# WB32F10x register map
File version: 1.2
CPU: CM3 r2p0, little endian, MPU, no FPU, 4 interrupt priority bits
Registers are 32-bit, read-write, reset 0x0 unless marked. A register's access mark holds for its fields unless they carry their own. Offsets are from the block's base; [hi:lo] are bit positions; lines under a group give offsets from that group; {n}, {i} and the like mark numbered series; 'fields as' and 'values as' point back to an identical list.

## ADC — Analog to digital conversion
Base 0x40003C00
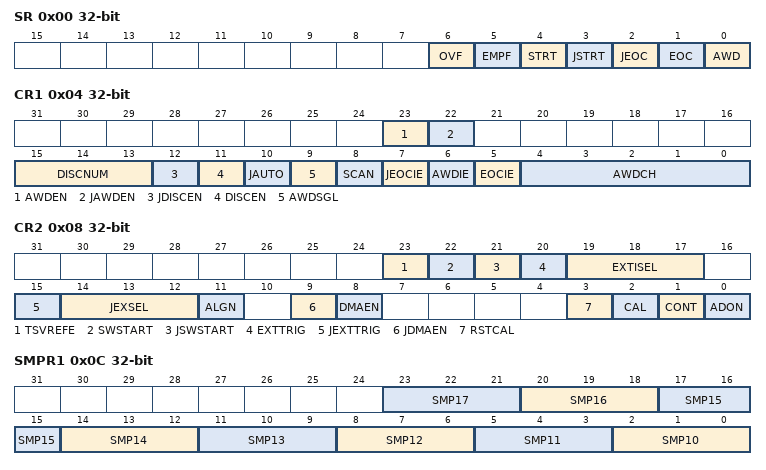
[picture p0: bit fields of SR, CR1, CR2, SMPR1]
0x00 SR — ADC status register
  [6] OVF — Regular channel FIFO overflow flag
  [5] EMPF — Regular channel FIFO empty flag
  [4] STRT — Regular channel Start flag
  [3] JSTRT — Injected channel Start flag
  [2] JEOC — Injected channel end of conversion
  [1] EOC — End of conversion
  [0] AWD — Analog watchdog flag
0x04 CR1 — ADC control register 1
  [23] AWDEN — Analog watchdog enable on regular channels
  [22] JAWDEN — Analog watchdog enable on injected channels
  [15:13] DISCNUM — Discontinuous mode channel count
    {v}=Channel_Count ({v+1}Channel) (v=0..7)
  [12] JDISCEN — Discontinuous mode on injected channels
  [11] DISCEN — Discontinuous mode on regular channels
  [10] JAUTO — Automatic Injected Group conversion
  [9] AWDSGL — Enable the watchdog on a single channel in scan mode
  [8] SCAN — Scan mode
  [7] JEOCIE — Interrupt enable for injected channels
  [6] AWDIE — Analog watchdog interrupt enable
  [5] EOCIE — Interrupt enable for EOC
  [4:0] AWDCH — Analog watchdog channel select bits
    {v}=Channel{v} (v=0..17)
0x08 CR2 — ADC control register 2
  [23] TSVREFE — Temperature sensor and VREFINT enable
  [22] SWSTART — Start conversion of regular channels
  [21] JSWSTART — Start conversion of injected channels
  [20] EXTTRIG — External trigger conversion mode for regular channels
  [19:17] EXTISEL — External event select for regular group
    0=TIM1_CC1 (Timer1 channel_1 capture/compare event); 1=TIM1_CC2 (Timer1 channel_2 capture/compare event); 2=TIM1_CC3 (Timer1 channel_3 capture/compare event); 3=TIM2_CC2 (Timer2 channel_2 capture/compare event); 4=TIM3_TRGO (Timer1 trigger output event); 5=TIM4_CC4 (Timer4 channel_4 capture/compare event); 6=EXTI11 (External line 11 event); 7=SWSTART (Software start event for regular channels)
  [15] JEXTTRIG — External trigger conversion mode for injected channels
  [14:12] JEXSEL — External event select for injected group
    0=TIM1_TRGO (Timer1 trigger output event); 1=TIM1_CC4 (Timer1 channel_4 capture/compare event); 2=TIM2_TRGO (Timer2 trigger output event); 3=TIM2_CC1 (Timer2 channel_1 capture/compare event); 4=TIM3_CC4 (Timer3 channel_4 capture/compare event); 5=TIM4_TRGO (Timer4 trigger output event); 6=EXTI15 (External line 15 event); 7=JSWSTART (Software start event for injected channels)
  [11] ALGN — Data alignment
  [9] JDMAEN — Injected channel DMA enable
  [8] DMAEN — Regular channel DMA enable
  [3] RSTCAL — Reset calibration
  [2] CAL — A/D calibration
  [1] CONT — Continuous conversion
  [0] ADON — A/D on-off controller
0x0C SMPR1 — ADC sample time register 1
  [3n-28:3n-30] SMP{n} (n=10..17) — ADC Channel {n} Sample time selection
    0=SampleTime 1.5 cycles; 1=SampleTime 7.5 cycles; 1=SampleTime 13.5 cycles; 3=SampleTime 28.5 cycles; 4=SampleTime 41.5 cycles; 5=SampleTime 55.5 cycles; 6=SampleTime 71.5 cycles; 7=SampleTime 239.5 cycles
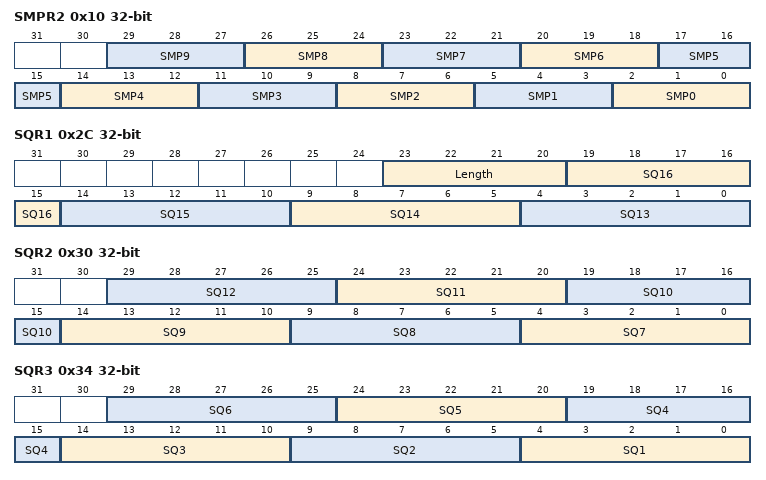
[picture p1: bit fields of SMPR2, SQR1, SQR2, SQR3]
0x10 SMPR2 — ADC sample time register 2
  [3n+2:3n] SMP{n} (n=0..9) — ADC Channel {n} Sample time selection
    values as SMPR1.SMP10
{0x10+4i} JOFR{i} (i=1..4) — ADC injected channel data offset register {i}
  [11:0] JOFFSET{i} — Data offset for injected channel {i}
0x24 HTR reset 0xFFF — ADC watchdog high threshold register
  [11:0] HT — Analog watchdog high threshold
0x28 LTR — ADC watchdog low threshold register
  [11:0] LT — Analog watchdog low threshold
0x2C SQR1 — ADC regular sequence register 1
  [23:20] Length — Regular channel sequence length
  [5n-61:5n-65] SQ{n} (n=13..16) — {n}th conversion in regular sequence
0x30 SQR2 — ADC regular sequence register 2
  [5n-31:5n-35] SQ{n} (n=7..12) — {n}th conversion in regular sequence
0x34 SQR3 — ADC regular sequence register 3
  [5n-1:5n-5] SQ{n} (n=1..6) — {n}th conversion in regular sequence
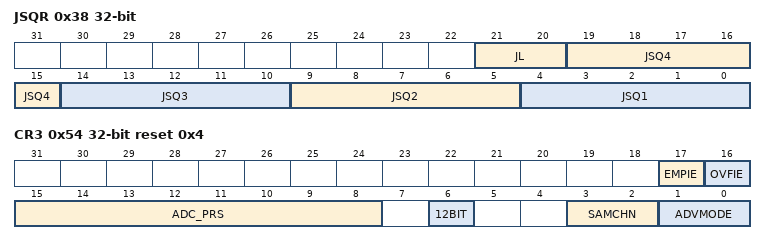
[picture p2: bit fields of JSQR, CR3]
0x38 JSQR — ADC injected sequence register
  [21:20] JL — Injected sequence length
    0=Length (1 conversion); 1=Length (2 conversions); 1=Length (3 conversions); 3=Length (4 conversions)
  [5n-1:5n-5] JSQ{n} (n=1..4) — {n}st conversion in injected sequence
{0x38+4i} JDR{i} (i=1..4) ro — ADC injected data register {i}
  [15:0] JDATA%s — Injected data %s
0x4C DR ro — ADC regular data register
  [15:0] DATA — Regular data
0x54 CR3 reset 0x4 — ADC control register 3
  [17] EMPIE — ADC fifo empty interrupt enable
  [16] OVFIE — ADC fifo overflow interrupt enable
  [15:8] ADC_PRS — Prescaler to the apb clock input
  [6] 12BIT — 12-bit enable
  [3:2] SAMCHN — SAMCHN bits
  [1:0] ADVMODE — Advance mode config
0x58 JDMAR — Injected data
  [15:0] JDMAR
